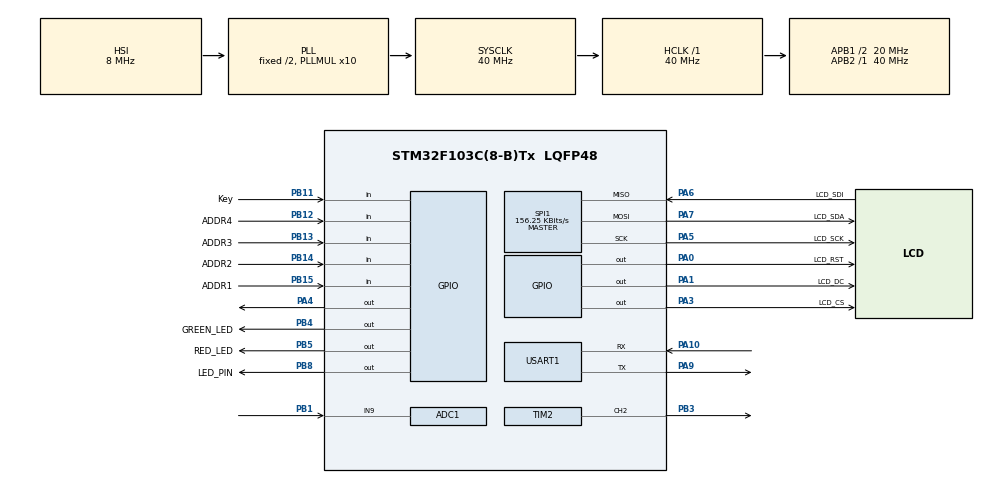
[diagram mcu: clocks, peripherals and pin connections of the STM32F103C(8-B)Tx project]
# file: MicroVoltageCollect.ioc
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ADC1.Channel-7\#ChannelRegularConversion=ADC_CHANNEL_9
ADC1.NbrOfConversionFlag=1
ADC1.Rank-7\#ChannelRegularConversion=1
ADC1.SamplingTime-7\#ChannelRegularConversion=ADC_SAMPLETIME_1CYCLE_5
ADC1.master=1
Mcu.Family=STM32F1
Mcu.Name=STM32F103C(8-B)Tx
Mcu.Package=LQFP48
NVIC.PriorityGroup=NVIC_PRIORITYGROUP_2
PA0-WKUP.GPIO_Label=LCD_RST
PA0-WKUP.Signal=GPIO_Output
PA1.GPIO_Label=LCD_DC
PA1.GPIO_Speed=GPIO_SPEED_FREQ_HIGH
PA1.PinState=GPIO_PIN_SET
PA1.Signal=GPIO_Output
PA10.Mode=Asynchronous
PA10.Signal=USART1_RX
PA13.Mode=Serial_Wire
PA13.Signal=SYS_JTMS-SWDIO
PA14.Mode=Serial_Wire
PA14.Signal=SYS_JTCK-SWCLK
PA3.GPIO_Label=LCD_CS
PA3.GPIO_PuPd=GPIO_PULLUP
PA3.GPIO_Speed=GPIO_SPEED_FREQ_HIGH
PA3.PinState=GPIO_PIN_SET
PA3.Signal=GPIO_Output
PA4.GPIO_PuPd=GPIO_PULLUP
PA4.GPIO_Speed=GPIO_SPEED_FREQ_HIGH
PA4.PinState=GPIO_PIN_SET
PA4.Signal=GPIO_Output
PA5.GPIO_Label=LCD_SCK
PA5.Mode=Full_Duplex_Master
PA5.Signal=SPI1_SCK
PA6.GPIO_Label=LCD_SDI
PA6.Mode=Full_Duplex_Master
PA6.Signal=SPI1_MISO
PA7.GPIO_Label=LCD_SDA
PA7.Mode=Full_Duplex_Master
PA7.Signal=SPI1_MOSI
PA9.Mode=Asynchronous
PA9.Signal=USART1_TX
PB1.Signal=ADCx_IN9
PB11.GPIO_Label=Key
PB11.Signal=GPIO_Input
PB12.GPIO_Label=ADDR4
PB12.Signal=GPIO_Input
PB13.GPIO_Label=ADDR3
PB13.Signal=GPIO_Input
PB14.GPIO_Label=ADDR2
PB14.Signal=GPIO_Input
PB15.GPIO_Label=ADDR1
PB15.Signal=GPIO_Input
PB3.Signal=S_TIM2_CH2
PB4.GPIO_Label=GREEN_LED
PB4.GPIO_PuPd=GPIO_PULLUP
PB4.GPIO_Speed=GPIO_SPEED_FREQ_HIGH
PB4.PinState=GPIO_PIN_RESET
PB4.Signal=GPIO_Output
PB5.GPIO_Label=RED_LED
PB5.GPIO_PuPd=GPIO_PULLDOWN
PB5.GPIO_Speed=GPIO_SPEED_FREQ_HIGH
PB5.PinState=GPIO_PIN_SET
PB5.Signal=GPIO_Output
PB8.GPIO_Label=LED_PIN
PB8.Signal=GPIO_Output
ProjectManager.HeapSize=0x200
ProjectManager.StackSize=0x400
ProjectManager.TargetToolchain=MDK-ARM V5
RCC.ADCPresc=RCC_ADCPCLK2_DIV6
RCC.AHBFreq_Value=40000000
RCC.APB1CLKDivider=RCC_HCLK_DIV2
RCC.APB1Freq_Value=20000000
RCC.APB1TimFreq_Value=40000000
RCC.APB2Freq_Value=40000000
RCC.APB2TimFreq_Value=40000000
RCC.HCLKFreq_Value=40000000
RCC.HSE_VALUE=12000000
RCC.PLLMUL=RCC_PLL_MUL10
RCC.SYSCLKFreq_VALUE=40000000
RCC.SYSCLKSource=RCC_SYSCLKSOURCE_PLLCLK
RCC.USBFreq_Value=40000000
SH.ADCx_IN9.0=ADC1_IN9,IN9
SH.S_TIM2_CH2.0=TIM2_CH2,PWM Generation2 CH2
SPI1.BaudRatePrescaler=SPI_BAUDRATEPRESCALER_256
SPI1.CRCCalculation=SPI_CRCCALCULATION_DISABLE
SPI1.CalculateBaudRate=156.25 KBits/s
SPI1.Direction=SPI_DIRECTION_2LINES
SPI1.Mode=SPI_MODE_MASTER
SPI1.VirtualType=VM_MASTER
TIM2.Channel-PWM\ Generation2\ CH2=TIM_CHANNEL_2
TIM2.Period=1000
TIM2.Prescaler=0
USART1.VirtualMode=VM_ASYNC
VP_TIM2_VS_ClockSourceINT.Mode=Internal
board=custom

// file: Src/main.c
/* USER CODE BEGIN Header */
/**
  ******************************************************************************
  * @file           : main.c
  * @brief          : Main program body
  ******************************************************************************
  * @attention
  *
  * <h2><center>&copy; Copyright (c) 2020 STMicroelectronics.
  * All rights reserved.</center></h2>
  *
  * This software component is licensed by ST under BSD 3-Clause license,
  * the "License"; You may not use this file except in compliance with the
  * License. You may obtain a copy of the License at:
  *                        opensource.org/licenses/BSD-3-Clause
  *
  ******************************************************************************
  */
/* USER CODE END Header */
#include "main.h"
#include "adc.h"
#include "spi.h"
#include "tim.h"
#include "usart.h"
#include "gpio.h"

/* USER CODE BEGIN Includes */
#include "lcd.h"
#include <string.h>
#include <stdio.h>
/* USER CODE END Includes */

/* USER CODE BEGIN PV */

/* USER CODE BEGIN PV */
/* Private variables ---------------------------------------------------------*/

/* USER CODE END PV */

void SystemClock_Config(void);

int main(void)
{

  /* MCU Configuration--------------------------------------------------------*/

  /* Reset of all peripherals, Initializes the Flash interface and the Systick. */
  HAL_Init();

  /* Configure the system clock */
  SystemClock_Config();

  /* Initialize all configured peripherals */
  MX_GPIO_Init();
  MX_SPI1_Init();
  MX_ADC1_Init();
  MX_USART1_UART_Init();
  MX_TIM2_Init();
  /* USER CODE BEGIN 2 */

/* USER CODE BEGIN 2 */
	HAL_GPIO_WritePin(RED_LED_GPIO_Port,RED_LED_Pin,GPIO_PIN_RESET);
	HAL_GPIO_WritePin(GREEN_LED_GPIO_Port,GREEN_LED_Pin,GPIO_PIN_SET);

  /* USER CODE END 2 */

  /* Infinite loop */
  while (1)
  {

    /* USER CODE BEGIN 3 */
		play_music();

		printf("\n\r ***** START PRINTF ADC INFO ******** \r\n\n");
		HAL_Delay(5000);

	}
  /* USER CODE END 3 */
}

void SystemClock_Config(void)
{
  RCC_OscInitTypeDef RCC_OscInitStruct = {0};
  RCC_ClkInitTypeDef RCC_ClkInitStruct = {0};
  RCC_PeriphCLKInitTypeDef PeriphClkInit = {0};

  /** Initializes the RCC Oscillators according to the specified parameters
  * in the RCC_OscInitTypeDef structure.
  */
  RCC_OscInitStruct.OscillatorType = RCC_OSCILLATORTYPE_HSI;
  RCC_OscInitStruct.HSIState = RCC_HSI_ON;
  RCC_OscInitStruct.HSICalibrationValue = RCC_HSICALIBRATION_DEFAULT;
  RCC_OscInitStruct.PLL.PLLState = RCC_PLL_ON;
  RCC_OscInitStruct.PLL.PLLSource = RCC_PLLSOURCE_HSI_DIV2;
  RCC_OscInitStruct.PLL.PLLMUL = RCC_PLL_MUL10;
  if (HAL_RCC_OscConfig(&RCC_OscInitStruct) != HAL_OK)
  {
    Error_Handler();
  }
  /** Initializes the CPU, AHB and APB buses clocks
  */
  RCC_ClkInitStruct.ClockType = RCC_CLOCKTYPE_HCLK|RCC_CLOCKTYPE_SYSCLK
                              |RCC_CLOCKTYPE_PCLK1|RCC_CLOCKTYPE_PCLK2;
  RCC_ClkInitStruct.SYSCLKSource = RCC_SYSCLKSOURCE_PLLCLK;
  RCC_ClkInitStruct.AHBCLKDivider = RCC_SYSCLK_DIV1;
  RCC_ClkInitStruct.APB1CLKDivider = RCC_HCLK_DIV2;
  RCC_ClkInitStruct.APB2CLKDivider = RCC_HCLK_DIV1;

  if (HAL_RCC_ClockConfig(&RCC_ClkInitStruct, FLASH_LATENCY_1) != HAL_OK)
  {
    Error_Handler();
  }
  PeriphClkInit.PeriphClockSelection = RCC_PERIPHCLK_ADC;
  PeriphClkInit.AdcClockSelection = RCC_ADCPCLK2_DIV6;
  if (HAL_RCCEx_PeriphCLKConfig(&PeriphClkInit) != HAL_OK)
  {
    Error_Handler();
  }
}

void Error_Handler(void)
{
}

/************************ (C) COPYRIGHT STMicroelectronics *****END OF FILE****/
